# STM32U59x register map
File version: 0.2
Registers are 32-bit, read-write, reset 0x0 unless marked. A register's access mark holds for its fields unless they carry their own. Offsets are from the block's base; [hi:lo] are bit positions; {n}, {i} and the like mark numbered series; 'fields as' and 'values as' point back to an identical list.

## RCC (part 2 of 2) — Reset and clock control
Base 0x46020C00
Same registers: SEC_RCC 0x56020C00
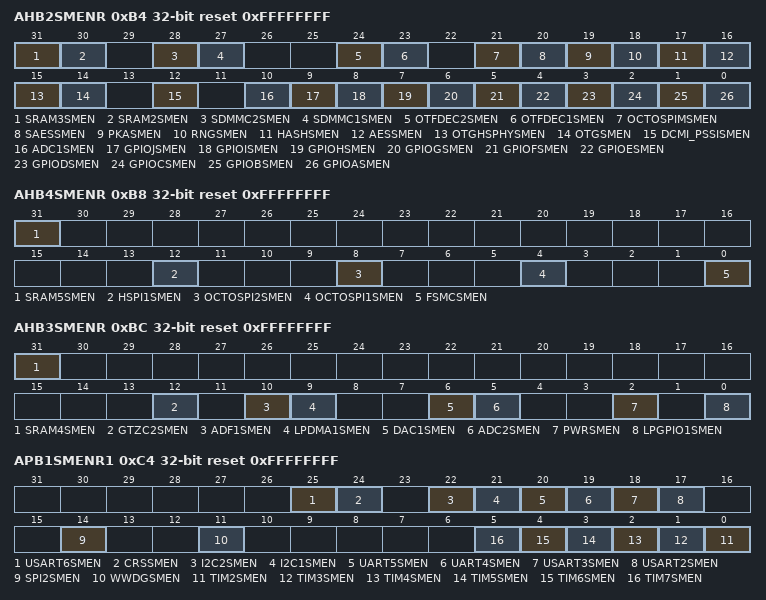
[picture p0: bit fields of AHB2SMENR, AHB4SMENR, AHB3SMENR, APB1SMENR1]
0xB4 AHB2SMENR reset 0xFFFFFFFF — AHB2 peripheral clocks enable in Sleep and Stop modes register
  [31] SRAM3SMEN — SRAM3 clocks enable during Sleep and Stop modes Set and cleared by software.
    0=SRAM3 clocks disabled by the clock gating during Sleep and Stop modes; 1=SRAM3 clocks enabled by the clock gating during Sleep and Stop modes
  [30] SRAM2SMEN — SRAM2 clocks enable during Sleep and Stop modes Set and cleared by software.
    0=SRAM2 clocks disabled by the clock gating during Sleep and Stop modes; 1=SRAM2 clocks enabled by the clock gating during Sleep and Stop modes
  [28] SDMMC2SMEN — SDMMC2 clocks enable during Sleep and Stop modes Set and cleared by software.
    0=SDMMC2 clocks disabled by the clock gating during Sleep and Stop modes; 1=SDMMC2 clocks enabled by the clock gating during Sleep and Stop modes
  [27] SDMMC1SMEN — SDMMC1 clocks enable during Sleep and Stop modes Set and cleared by software.
    0=SDMMC1 clocks disabled by the clock gating during Sleep and Stop modes; 1=SDMMC1 clocks enabled by the clock gating during Sleep and Stop modes
  [24] OTFDEC2SMEN — OTFDEC2 clocks enable during Sleep and Stop modes Set and cleared by software.
    0=OTFDEC2 clocks disabled by the clock gating during Sleep and Stop modes; 1=OTFDEC2 clocks enabled by the clock gating during Sleep and Stop modes
  [23] OTFDEC1SMEN — OTFDEC1 clocks enable during Sleep and Stop modes Set and cleared by software.
    0=OTFDEC1 clocks disabled by the clock gating during Sleep and Stop modes; 1=OTFDEC1 clocks enabled by the clock gating during Sleep and Stop modes
  [21] OCTOSPIMSMEN — OCTOSPIM clocks enable during Sleep and Stop modes Set and cleared by software.
    0=OCTOSPIM clocks disabled by the clock gating during Sleep and Stop modes; 1=OCTOSPIM clocks enabled by the clock gating during Sleep and Stop modes
  [20] SAESSMEN — SAES accelerator clocks enable during Sleep and Stop modes Set and cleared by software.
    0=SAES clocks disabled by the clock gating during Sleep and Stop modes; 1=SAES clocks enabled by the clock gating during Sleep and Stop modes
  [19] PKASMEN — PKA clocks enable during Sleep and Stop modes Set and cleared by software.
    0=PKA clocks disabled by the clock gating during Sleep and Stop modes; 1=PKA clocks enabled by the clock gating during Sleep and Stop modes
  [18] RNGSMEN — Random number generator (RNG) clocks enable during Sleep and Stop modes Set and cleared by software.
    0=RNG clocks disabled by the clock gating during Sleep and Stop modes; 1=RNG clocks enabled by the clock gating during Sleep and Stop modes
  [17] HASHSMEN — HASH clock enable during Sleep and Stop modes Set and cleared by software
    0=HASH clocks disabled by the clock gating during Sleep and Stop modes; 1=HASH clocks enabled by the clock gating during Sleep and Stop modes
  [16] AESSMEN — AES clock enable during Sleep and Stop modes Set and cleared by software
    0=AES clocks disabled by the clock gating during Sleep and Stop modes; 1=AES clocks enabled by the clock gating during Sleep and Stop modes
  [15] OTGHSPHYSMEN — OTG_HS PHY clock enable during Sleep and Stop modes Set and cleared by software Note: This bit is only available in STM32U59x/5Ax. It is reserved in STM32U575/585.
    0=OTG_HS PHY clocks disabled by the clock gating during Sleep and Stop modes; 1=OTG_HS PHY clocks enabled by the clock gating during Sleep and Stop modes
  [14] OTGSMEN — OTG_FS and OTG_HS clocks enable during Sleep and Stop modes Set and cleared by software. Note: This bit impacts OTG_FS in STM32U575/585 and OTG_HS in STM32U59x/5Ax.
    0=OTG_FS and OTG_HS clocks disabled by the clock gating during Sleep and Stop modes; 1=OTG_FS and OTG_HS clocks enabled by the clock gating during Sleep and Stop modes
  [12] DCMI_PSSISMEN — DCMI and PSSI clocks enable during Sleep and Stop modes Set and cleared by software.
    0=DCMI and PSSI clocks disabled by the clock gating during Sleep and Stop modes; 1=DCMI and PSSI clocks enabled by the clock gating during Sleep and Stop modes
  [10] ADC1SMEN — ADC1 and ADC2 clocks enable during Sleep and Stop modes Set and cleared by software. Note: This bit impacts ADC1 in STM32U575/585 and ADC1/ADC2 in STM32U59x/5Ax.
    0=ADC1 and ADC2 clocks disabled by the clock gating during Sleep and Stop modes; 1=ADC1 and ADC2 clocks enabled by the clock gating during Sleep and Stop modes
  [9] GPIOJSMEN — IO port J clocks enable during Sleep and Stop modes Set and cleared by software. Note: This bit is only available in STM32U59x/5Ax. It is reserved in STM32U575/585.
    0=IO port J clocks disabled by the clock gating during Sleep and Stop modes; 1=IO port J clocks enabled by the clock gating during Sleep and Stop modes
  [8] GPIOISMEN — IO port I clocks enable during Sleep and Stop modes Set and cleared by software.
    0=IO port I clocks disabled by the clock gating during Sleep and Stop modes; 1=IO port I clocks enabled by the clock gating during Sleep and Stop modes
  [7] GPIOHSMEN — IO port H clocks enable during Sleep and Stop modes Set and cleared by software.
    0=IO port H clocks disabled by the clock gating during Sleep and Stop modes; 1=IO port H clocks enabled by the clock gating during Sleep and Stop modes
  [6] GPIOGSMEN — IO port G clocks enable during Sleep and Stop modes Set and cleared by software.
    0=IO port G clocks disabled by the clock gating during Sleep and Stop modes; 1=IO port G clocks enabled by the clock gating during Sleep and Stop modes
  [5] GPIOFSMEN — IO port F clocks enable during Sleep and Stop modes Set and cleared by software.
    0=IO port F clocks disabled by the clock gating during Sleep and Stop modes; 1=IO port F clocks enabled by the clock gating during Sleep and Stop modes
  [4] GPIOESMEN — IO port E clocks enable during Sleep and Stop modes Set and cleared by software.
    0=IO port E clocks disabled by the clock gating during Sleep and Stop modes; 1=IO port E clocks enabled by the clock gating during Sleep and Stop modes
  [3] GPIODSMEN — IO port D clocks enable during Sleep and Stop modes Set and cleared by software.
    0=IO port D clocks disabled by the clock gating during Sleep and Stop modes; 1=IO port D clocks enabled by the clock gating during Sleep and Stop modes
  [2] GPIOCSMEN — IO port C clocks enable during Sleep and Stop modes Set and cleared by software.
    0=IO port C clocks disabled by the clock gating during Sleep and Stop modes; 1=IO port C clocks enabled by the clock gating during Sleep and Stop modes
  [1] GPIOBSMEN — IO port B clocks enable during Sleep and Stop modes Set and cleared by software.
    0=IO port B clocks disabled by the clock gating during Sleep and Stop modes; 1=IO port B clocks enabled by the clock gating during Sleep and Stop modes
  [0] GPIOASMEN — IO port A clocks enable during Sleep and Stop modes Set and cleared by software.
    0=IO port A clocks disabled by the clock gating during Sleep and Stop modes; 1=IO port A clocks enabled by the clock gating during Sleep and Stop modes
0xB8 AHB4SMENR reset 0xFFFFFFFF — AHB4 peripheral clocks enable in Sleep and Stop modes register
  [31] SRAM5SMEN — SRAM5 clocks enable during Sleep and Stop modes Set and cleared by software. Note: This bit is only available in STM32U59x/5Ax. It is reserved in STM32U575/585.
    0=SRAM5 clocks disabled by the clock gating during Sleep and Stop modes; 1=SRAM5 clocks enabled by the clock gating during Sleep and Stop modes
  [12] HSPI1SMEN — HSPI1 clocks enable during Sleep and Stop modes Set and cleared by software. Note: This bit is only available in STM32U59x/5Ax. It is reserved in STM32U575/585.
    0=HSPI1 clocks disabled by the clock gating during Sleep and Stop modes; 1=HSP1I clocks enabled by the clock gating during Sleep and Stop modes
  [8] OCTOSPI2SMEN — OCTOSPI2 clocks enable during Sleep and Stop modes Set and cleared by software.
    0=OCTOSPI2 clocks disabled by the clock gating during Sleep and Stop modes; 1=OCTOSPI2 clocks enabled by the clock gating during Sleep and Stop modes
  [4] OCTOSPI1SMEN — OCTOSPI1 clocks enable during Sleep and Stop modes Set and cleared by software.
    0=OCTOSPI1 clocks disabled by the clock gating during Sleep and Stop modes; 1=OCTOSPI1 clocks enabled by the clock gating during Sleep and Stop modes
  [0] FSMCSMEN — FSMC clocks enable during Sleep and Stop modes Set and cleared by software.
    0=FSMC clocks disabled by the clock gating during Sleep and Stop modes; 1=FSMC clocks enabled by the clock gating during Sleep and Stop modes
0xBC AHB3SMENR reset 0xFFFFFFFF — AHB3 peripheral clocks enable in Sleep and Stop modes register
  [31] SRAM4SMEN, [12] GTZC2SMEN, [10] ADF1SMEN, [9] LPDMA1SMEN, [6] DAC1SMEN, [5] ADC2SMEN, [2] PWRSMEN, [0] LPGPIO1SMEN
0xC4 APB1SMENR1 reset 0xFFFFFFFF — APB1 peripheral clocks enable in Sleep and Stop modes register 1
  [25] USART6SMEN — USART6 clock enable during Sleep and Stop modes Set and cleared by software. Note: This bit is only available in STM32U59x/5Ax. It is reserved in STM32U575/585.
    0=USART6 clocks disabled by the clock gating during Sleep and Stop modes; 1=USART6 clocks enabled by the clock gating during Sleep and Stop modes
  [24] CRSSMEN — CRS clock enable during Sleep and Stop modes Set and cleared by software.
    0=CRS clocks disabled by the clock gating during Sleep and Stop modes; 1=CRS clocks enabled by the clock gating during Sleep and Stop modes
  [22] I2C2SMEN — I2C2 clocks enable during Sleep and Stop modes Set and cleared by software. Note: This bit must be set to allow the peripheral to wake up from Stop modes.
    0=I2C2 clocks disabled by the clock gating during Sleep and Stop modes; 1=I2C2 clocks enabled by the clock gating during Sleep and Stop modes
  [21] I2C1SMEN — I2C1 clocks enable during Sleep and Stop modes Set and cleared by software. Note: This bit must be set to allow the peripheral to wake up from Stop modes.
    0=I2C1 clocks disabled by the clock gating during Sleep and Stop modes; 1=I2C1 clocks enabled by the clock gating during Sleep and Stop modes
  [20] UART5SMEN — UART5 clocks enable during Sleep and Stop modes Set and cleared by software. Note: This bit must be set to allow the peripheral to wake up from Stop modes.
    0=UART5 clocks disabled by the clock gating during Sleep and Stop modes; 1=UART5 clocks enabled by the clock gating during Sleep and Stop modes
  [19] UART4SMEN — UART4 clocks enable during Sleep and Stop modes Set and cleared by software. Note: This bit must be set to allow the peripheral to wake up from Stop modes.
    0=UART4 clocks disabled by the clock gating during Sleep and Stop modes; 1=UART4 clocks enabled by the clock gating during Sleep and Stop modes
  [18] USART3SMEN — USART3 clocks enable during Sleep and Stop modes Set and cleared by software. Note: This bit must be set to allow the peripheral to wake up from Stop modes.
    0=USART3 clocks disabled by the clock gating during Sleep and Stop modes; 1=USART3 clocks enabled by the clock gating during Sleep and Stop modes
  [17] USART2SMEN — USART2 clocks enable during Sleep and Stop modes Set and cleared by software. Note: This bit must be set to allow the peripheral to wake up from Stop modes.
    0=USART2 clocks disabled by the clock gating during Sleep and Stop modes; 1=USART2 clocks enabled by the clock gating during Sleep and Stop modes
  [14] SPI2SMEN — SPI2 clocks enable during Sleep and Stop modes Set and cleared by software. Note: This bit must be set to allow the peripheral to wake up from Stop modes.
    0=SPI2 clocks disabled by the clock gating during Sleep and Stop modes; 1=SPI2 clocks enabled by the clock gating during Sleep and Stop modes
  [11] WWDGSMEN — Window watchdog clocks enable during Sleep and Stop modes Set and cleared by software. This bit is forced to 1 by hardware when the hardware WWDG option is activated.
    0=Window watchdog clocks disabled by the clock gating during Sleep and Stop modes; 1=Window watchdog clocks enabled by the clock gating during Sleep and Stop modes
  [n-2] TIM{n}SMEN (n=2..7) — TIM{n} clocks enable during Sleep and Stop modes Set and cleared by software.
    0=TIM{n} clocks disabled by the clock gating during Sleep and Stop modes; 1=TIM{n} clocks enabled by the clock gating during Sleep and Stop modes
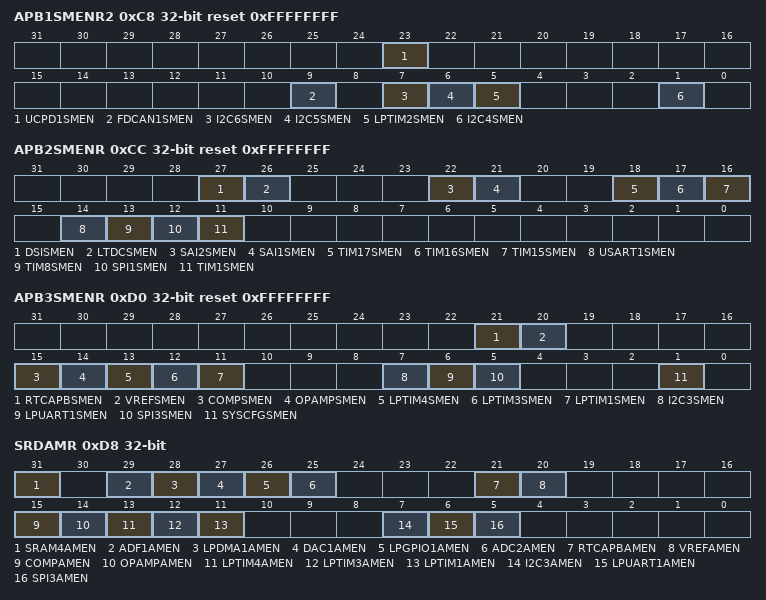
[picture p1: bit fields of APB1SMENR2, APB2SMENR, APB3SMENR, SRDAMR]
0xC8 APB1SMENR2 reset 0xFFFFFFFF — APB1 peripheral clocks enable in Sleep and Stop modes register 2
  [23] UCPD1SMEN — UCPD1 clocks enable during Sleep and Stop modes Set and cleared by software.
    0=UCPD1 clocks disabled by the clock gating during Sleep and Stop modes; 1=UCPD1 clocks enabled by the clock gating during Sleep and Stop modes
  [9] FDCAN1SMEN — FDCAN1 clocks enable during Sleep and Stop modes Set and cleared by software.
    0=FDCAN1 clocks disabled by the clock gating during Sleep and Stop modes; 1=FDCAN1 clocks enabled by the clock gating during Sleep and Stop modes
  [7] I2C6SMEN — I2C6 clocks enable during Sleep and Stop modes Set and cleared by software Note: This bit must be set to allow the peripheral to wake up from Stop modes. This bit is only available in STM32U59x/5Ax. It is reserved in STM32U575/585.
    0=I2C6 clocks disabled by the clock gating during Sleep and Stop modes; 1=I2C6 clocks enabled by the clock gating during Sleep and Stop modes
  [6] I2C5SMEN — I2C5 clocks enable during Sleep and Stop modes Set and cleared by software Note: This bit must be set to allow the peripheral to wake up from Stop modes. This bit is only available in STM32U59x/5Ax. It is reserved in STM32U575/585.
    0=I2C5 clocks disabled by the clock gating during Sleep and Stop modes; 1=I2C5 clocks enabled by the clock gating during Sleep and Stop modes
  [5] LPTIM2SMEN — LPTIM2 clocks enable during Sleep and Stop modes Set and cleared by software. Note: This bit must be set to allow the peripheral to wake up from Stop modes.
    0=LPTIM2 clocks disabled by the clock gating during Sleep and Stop modes; 1=LPTIM2 clocks enabled by the clock gating during Sleep and Stop modes
  [1] I2C4SMEN — I2C4 clocks enable during Sleep and Stop modes Set and cleared by software Note: This bit must be set to allow the peripheral to wake up from Stop modes.
    0=I2C4 clocks disabled by the clock gating during Sleep and Stop modes; 1=I2C4 clocks enabled by the clock gating during Sleep and Stop modes
0xCC APB2SMENR reset 0xFFFFFFFF — APB2 peripheral clocks enable in Sleep and Stop modes register
  [27] DSISMEN — DSI clocks enable during Sleep and Stop modes Set and cleared by software. Note: This bit is only available in STM32U59x/5Ax. It is reserved in STM32U575/585.
    0=DSI clocks disabled by the clock gating during Sleep and Stop modes; 1=DSI clocks enabled by the clock gating during Sleep and Stop modes
  [26] LTDCSMEN — LTDC clocks enable during Sleep and Stop modes Set and cleared by software. Note: This bit is only available in STM32U59x/5Ax. It is reserved in STM32U575/585.
    0=LTDC clocks disabled by the clock gating during Sleep and Stop modes; 1=LTDC clocks enabled by the clock gating during Sleep and Stop modes
  [22] SAI2SMEN — SAI2 clocks enable during Sleep and Stop modes Set and cleared by software.
    0=SAI2 clocks disabled by the clock gating during Sleep and Stop modes; 1=SAI2 clocks enabled by the clock gating during Sleep and Stop modes
  [21] SAI1SMEN — SAI1 clocks enable during Sleep and Stop modes Set and cleared by software.
    0=SAI1 clocks disabled by the clock gating during Sleep and Stop modes; 1=SAI1 clocks enabled by the clock gating during Sleep and Stop modes
  [18] TIM17SMEN — TIM17 clocks enable during Sleep and Stop modes Set and cleared by software.
    0=TIM17 clocks disabled by the clock gating during Sleep and Stop modes; 1=TIM17 clocks enabled by the clock gating during Sleep and Stop modes
  [17] TIM16SMEN — TIM16 clocks enable during Sleep and Stop modes Set and cleared by software.
    0=TIM16 clocks disabled by the clock gating during Sleep and Stop modes; 1=TIM16 clocks enabled by the clock gating during Sleep and Stop modes
  [16] TIM15SMEN — TIM15 clocks enable during Sleep and Stop modes Set and cleared by software.
    0=TIM15 clocks disabled by the clock gating during Sleep and Stop modes; 1=TIM15 clocks enabled by the clock gating during Sleep and Stop modes
  [14] USART1SMEN — USART1clocks enable during Sleep and Stop modes Set and cleared by software. Note: This bit must be set to allow the peripheral to wake up from Stop modes.
    0=USART1clocks disabled by the clock gating during Sleep and Stop modes; 1=USART1clocks enabled by the clock gating during Sleep and Stop modes
  [13] TIM8SMEN — TIM8 clocks enable during Sleep and Stop modes Set and cleared by software.
    0=TIM8 clocks disabled by the clock gating during Sleep and Stop modes; 1=TIM8 clocks enabled by the clock gating during Sleep and Stop modes
  [12] SPI1SMEN — SPI1 clocks enable during Sleep and Stop modes Set and cleared by software. Note: This bit must be set to allow the peripheral to wake up from Stop modes.
    0=SPI1 clocks disabled by the clock gating during Sleep and Stop modes; 1=SPI1 clocks enabled by the clock gating during Sleep and Stop modes
  [11] TIM1SMEN — TIM1 clocks enable during Sleep and Stop modes Set and cleared by software.
    0=TIM1 clocks disabled by the clock gating during Sleep and Stop modes; 1=TIM1 clocks enabled by the clock gating during Sleep and Stop modes
0xD0 APB3SMENR reset 0xFFFFFFFF — APB3 peripheral clocks enable in Sleep and Stop modes register
  [21] RTCAPBSMEN, [20] VREFSMEN, [15] COMPSMEN, [14] OPAMPSMEN, [13] LPTIM4SMEN, [12] LPTIM3SMEN, [11] LPTIM1SMEN, [7] I2C3SMEN, [6] LPUART1SMEN, [5] SPI3SMEN, [1] SYSCFGSMEN
0xD8 SRDAMR — Smart run domain peripheral autonomous mode register
  [31] SRAM4AMEN, [29] ADF1AMEN, [28] LPDMA1AMEN, [27] DAC1AMEN, [26] LPGPIO1AMEN, [25] ADC2AMEN, [21] RTCAPBAMEN, [20] VREFAMEN, [15] COMPAMEN, [14] OPAMPAMEN, [13] LPTIM4AMEN, [12] LPTIM3AMEN, [11] LPTIM1AMEN, [7] I2C3AMEN, [6] LPUART1AMEN, [5] SPI3AMEN
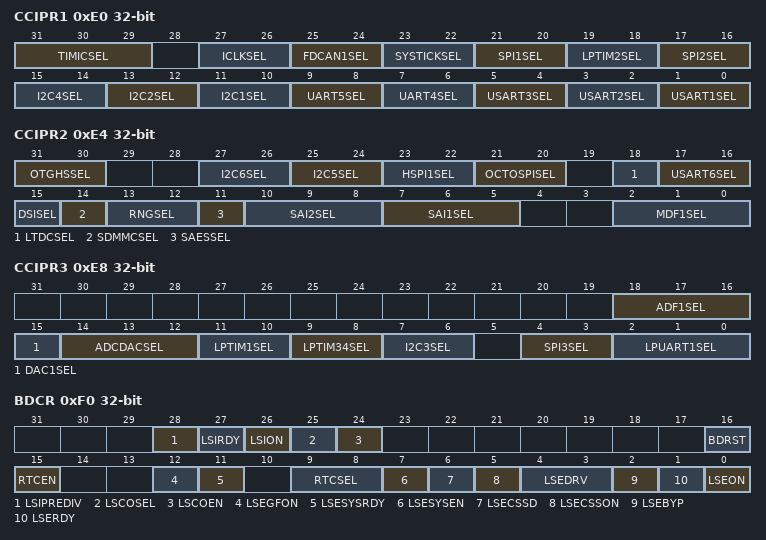
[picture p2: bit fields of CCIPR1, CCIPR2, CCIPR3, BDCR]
0xE0 CCIPR1 — peripherals independent clock configuration register 1
  [31:29] TIMICSEL, [27:26] ICLKSEL, [25:24] FDCAN1SEL, [23:22] SYSTICKSEL, [21:20] SPI1SEL, [19:18] LPTIM2SEL, [17:16] SPI2SEL, [15:14] I2C4SEL, [13:12] I2C2SEL, [11:10] I2C1SEL, [9:8] UART5SEL, [7:6] UART4SEL, [5:4] USART3SEL, [3:2] USART2SEL, [1:0] USART1SEL
0xE4 CCIPR2 — peripherals independent clock configuration register 2
  [31:30] OTGHSSEL — OTG_HS PHY kernel clock source selection These bits are used to select the OTG_HS PHY kernel clock source. Note: This field is only available in STM32U59x/5Ax. It is reserved in STM32U575/585.
    0=HSE selected; 1=PLL1 âPâ (pll1_q_ck) selected,; 2=HSE/2 selected; 3=PLL1 âPâ divided by 2 (pll1_p_ck/2) selected
  [27:26] I2C6SEL — I2C6 kernel clock source selection These bits are used to select the I2C6 kernel clock source. Note: The I2C6 is functional in Stop 0 and Stop 1 modes only when the kernel clock is HSI16 or MSIK. This field is only available in STM32U59x/5Ax. It is reserved in STM32U575/585.
    0=PCLK1 selected; 1=SYSCLK selected; 2=HSI16 selected; 3=MSIK selected
  [25:24] I2C5SEL — I2C5 kernel clock source selection These bits are used to select the I2C5 kernel clock source. Note: The I2C5 is functional in Stop 0 and Stop 1 modes only when the kernel clock is HSI16 or MSIK. This field is only available in STM32U59x/5Ax. It is reserved in STM32U575/585.
    values as I2C6SEL
  [23:22] HSPI1SEL — HSPI1 kernel clock source selection These bits are used to select the HSPI1 kernel clock source. Note: This field is only available in STM32U59x/5Ax. It is reserved in STM32U575/585.
    0=SYSCLK selected; 1=PLL1 âQâ (pll1_q_ck) selected, can be up to 200 MHz; 2=PLL2 âQâ (pll2_q_ck) selected, can be up to 200 MHz; 3=PLL3 âRâ (pll3_r_ck) selected, can be up to 200 MHz
  [21:20] OCTOSPISEL — OCTOSPI1 and OCTOSPI2 kernel clock source selection These bits are used to select the OCTOSPI1 and OCTOSPI2 kernel clock source.
    0=SYSCLK selected; 1=MSIK selected; 2=PLL1 âQâ (pll1_q_ck) selected, can be up to 200 MHz; 3=PLL2 âQâ (pll2_q_ck) selected, can be up to 200 MHz
  [18] LTDCSEL — LTDC kernel clock source selection This bit is used to select the LTDC kernel clock source. Note: This bit is only available in STM32U59x/5Ax. It is reserved in STM32U575/585.
    0=PLL3 âRâ (pll3_r_ck) selected; 1=PLL2 âRâ (pll2_r_ck) selected
  [17:16] USART6SEL — USART6 kernel clock source selection These bits are used to select the USART6 kernel clock source. Note: The USART6 is functional in Stop 0 and Stop 1 modes only when the kernel clock is HSI16 or MSIK. This field is only available in STM32U59x/5Ax. It is reserved in STM32U575/585.
    values as I2C6SEL
  [15] DSISEL — DSI kernel clock source selection This bit is used to select the DSI kernel clock source. Note: This bit is only available in STM32U59x/5Ax. It is reserved in STM32U575/585.
    0=DSI PHY PLL output selected; 1=PLL3 âPâ (pll3_p_ck) selected
  [14] SDMMCSEL — SDMMC1 and SDMMC2 kernel clock source selection This bit is used to select the SDMMC kernel clock source. It is recommended to change this bit only after reset and before enabling the SDMMC.
    0=ICLK clock selected; 1=PLL1 âPâ (pll1_p_ck) selected, in case higher than 48 MHz is needed (for SDR50 mode)
  [13:12] RNGSEL — RNGSEL kernel clock source selection These bits are used to select the RNG kernel clock source.
    0=HSI48 selected; 1=HSI48 / 2 selected, can be used in Range 4; 2=HSI16 selected
  [11] SAESSEL — SAES kernel clock source selection This bit is used to select the SAES kernel clock source.
    0=SHSI selected; 1=SHSI / 2 selected, can be used in Range 4
  [10:8] SAI2SEL — SAI2 kernel clock source selection These bits are used to select the SAI2 kernel clock source. others: reserved Note: If the selected clock is the external clock and this clock is stopped, a switch to another clock is impossible.
    0=PLL2 âPâ (pll2_p_ck) selected; 1=PLL3 âPâ (pll3_p_ck) selected; 2=PLL1 âPâ (pll1_p_ck) selected; 3=input pin AUDIOCLK selected; 4=HSI16 clock selected
  [7:5] SAI1SEL — SAI1 kernel clock source selection These bits are used to select the SAI1 kernel clock source. others: reserved Note: If the selected clock is the external clock and this clock is stopped, a switch to another clock is impossible.
    values as SAI2SEL
  [2:0] MDF1SEL — MDF1 kernel clock source selection These bits are used to select the MDF1 kernel clock source. others: reserved
    0=HCLK selected; 1=PLL1 âPâ (pll1_p_ck) selected; 2=PLL3 âQâ (pll3_q_ck) selected; 3=input pin AUDIOCLK selected; 4=MSIK clock selected
0xE8 CCIPR3 — peripherals independent clock configuration register 3
  [18:16] ADF1SEL, [15] DAC1SEL, [14:12] ADCDACSEL, [11:10] LPTIM1SEL, [9:8] LPTIM34SEL, [7:6] I2C3SEL, [4:3] SPI3SEL, [2:0] LPUART1SEL
0xF0 BDCR access per field — Backup domain control register
  [28] LSIPREDIV rw, [27] LSIRDY rw, [26] LSION rw, [25] LSCOSEL rw, [24] LSCOEN rw, [16] BDRST rw, [15] RTCEN rw, [12] LSEGFON rw, [11] LSESYSRDY ro, [9:8] RTCSEL rw, [7] LSESYSEN rw, [6] LSECSSD ro, [5] LSECSSON rw, [4:3] LSEDRV rw, [2] LSEBYP rw, [1] LSERDY ro, [0] LSEON rw
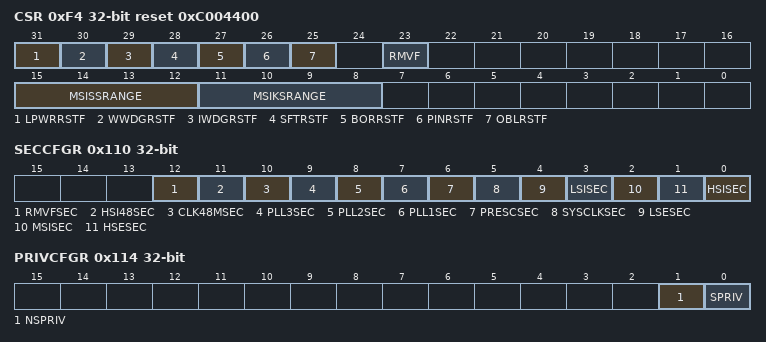
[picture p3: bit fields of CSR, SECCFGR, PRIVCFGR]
0xF4 CSR access per field reset 0xC004400 — control/status register
  [31] LPWRRSTF ro, [30] WWDGRSTF ro, [29] IWDGRSTF ro, [28] SFTRSTF ro, [27] BORRSTF ro, [26] PINRSTF ro, [25] OBLRSTF ro, [23] RMVF rw, [15:12] MSISSRANGE rw, [11:8] MSIKSRANGE rw
0x110 SECCFGR — secure configuration register
  [12] RMVFSEC, [11] HSI48SEC, [10] CLK48MSEC, [9] PLL3SEC, [8] PLL2SEC, [7] PLL1SEC, [6] PRESCSEC, [5] SYSCLKSEC, [4] LSESEC, [3] LSISEC, [2] MSISEC, [1] HSESEC, [0] HSISEC
0x114 PRIVCFGR — privilege configuration register
  [1] NSPRIV, [0] SPRIV
